AUTOSAR XML (schema 00050)
package /Pkg_DegManager_QM/ComponentTypes
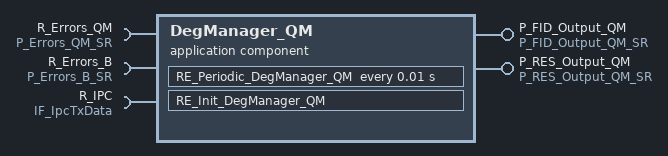
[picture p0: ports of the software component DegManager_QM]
  application sw component type DegManager_QM
    provide port P_FID_Output_QM: nonqueued-sender-com-spec{data-element=FID_QM, init-value=[0]}, provided-interface=P_FID_Output_QM_SR
    require port R_Errors_QM: nonqueued-receiver-com-spec{data-element=Errors_QM, init-value=constant-reference=init_Errors_QM}, required-interface=P_Errors_QM_SR
    require port R_Errors_B: nonqueued-receiver-com-spec{data-element=Errors_B, init-value=constant-reference=init_Errors_B}, required-interface=P_Errors_B_SR
    provide port P_RES_Output_QM: nonqueued-sender-com-spec=RES_QM, provided-interface=P_RES_Output_QM_SR
    require port R_IPC: client-com-spec=IPC_Write_v, required-interface=IF_IpcTxData
    behavior DegManager_QM_InternalBehavior: handle-termination-and-restart=NO-SUPPORT
      timing event TMT_RE_Periodic_DegManager_QM: start-on-event=RE_Periodic_DegManager_QM, period=0.01
      init event InitEvent: start-on-event=RE_Init_DegManager_QM
      port-api-options:
        enable-take-address=false, indirect-api=false, port=P_FID_Output_QM
        enable-take-address=false, indirect-api=false, port=R_Errors_B
        enable-take-address=false, indirect-api=false, port=R_Errors_QM
        enable-take-address=false, indirect-api=false, port=P_RES_Output_QM
        enable-take-address=false, indirect-api=false, port=R_IPC
      runnable RE_Periodic_DegManager_QM  # Periodic Runnable of Satellite
        data-receive-point-by-arguments:
          access REC_R_Errors_QM_Errors_QM: accessed-variable=R_Errors_QM.Errors_QM
          access REC_R_Errors_B_Errors_B: accessed-variable=R_Errors_B.Errors_B
        data-send-points:
          access SEND_P_FID_Output_QM_FID_QM: accessed-variable=P_FID_Output_QM.FID_QM
          access SEND_P_RES_Output_QM_RES_QM: accessed-variable=P_RES_Output_QM.RES_QM
        sync call SC_R_IPC_IPC_Write_v: operation=R_IPC.IPC_Write_v
      runnable RE_Init_DegManager_QM  # Init Runnable
  swc implementation DegManager_QM_Implementation: programming-language=C, vendor-id=0, behavior=DegManager_QM_InternalBehavior
    code-descriptors:
      code Default: artifact-descriptors=autosar-engineering-object=category=SWSRC
